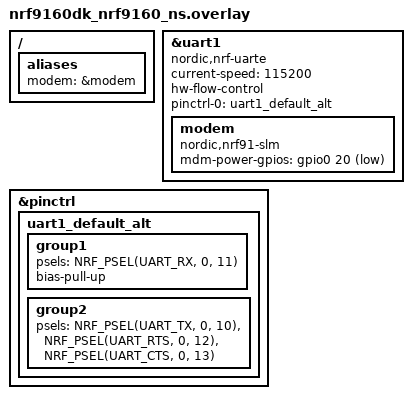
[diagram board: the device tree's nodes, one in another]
/ {
	aliases {
		modem = &modem;
	};
};

&uart1 {
	compatible = "nordic,nrf-uarte";
	current-speed = <115200>;
	hw-flow-control;
	status = "okay";

	pinctrl-0 = <&uart1_default_alt>;

	modem: modem {
		compatible = "nordic,nrf91-slm";
		status = "okay";
		mdm-power-gpios = <&gpio0 20 GPIO_ACTIVE_LOW>;
	};
};

&pinctrl {
	uart1_default_alt: uart1_default_alt {
		group1 {
			psels = <NRF_PSEL(UART_RX, 0, 11)>;
			bias-pull-up;
		};
		group2 {
			psels = <NRF_PSEL(UART_TX, 0, 10)>,
				<NRF_PSEL(UART_RTS, 0, 12)>,
				<NRF_PSEL(UART_CTS, 0, 13)>;
		};
	};
};
